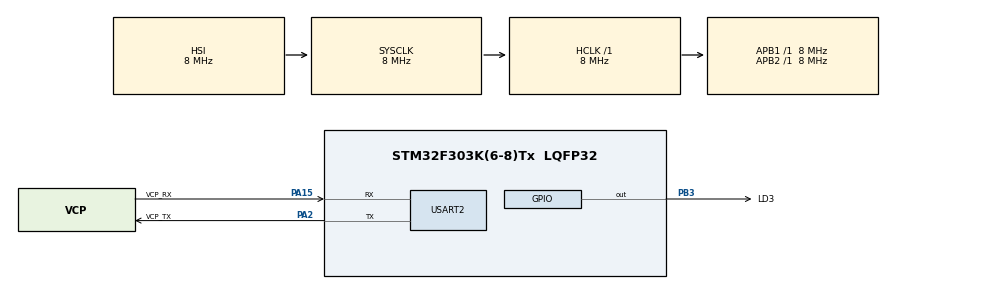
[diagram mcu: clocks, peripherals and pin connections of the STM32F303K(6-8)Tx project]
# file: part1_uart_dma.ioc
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Dma.Request0=USART2_RX
Dma.USART2_RX.0.Direction=DMA_PERIPH_TO_MEMORY
Dma.USART2_RX.0.Instance=DMA1_Channel6
Dma.USART2_RX.0.MemDataAlignment=DMA_MDATAALIGN_BYTE
Dma.USART2_RX.0.MemInc=DMA_MINC_ENABLE
Dma.USART2_RX.0.Mode=DMA_NORMAL
Dma.USART2_RX.0.PeriphDataAlignment=DMA_PDATAALIGN_BYTE
Dma.USART2_RX.0.PeriphInc=DMA_PINC_DISABLE
Dma.USART2_RX.0.Priority=DMA_PRIORITY_LOW
Mcu.Family=STM32F3
Mcu.Name=STM32F303K(6-8)Tx
Mcu.Package=LQFP32
NVIC.DMA1_Channel6_IRQn=true\:0\:0\:false\:false\:true\:false\:true\:true
NVIC.PriorityGroup=NVIC_PRIORITYGROUP_4
PA13.GPIO_Label=SWDIO
PA13.Mode=Serial_Wire
PA13.Signal=SYS_JTMS-SWDIO
PA14.GPIO_Label=SWCLK
PA14.Mode=Serial_Wire
PA14.Signal=SYS_JTCK-SWCLK
PA15.GPIO_Label=VCP_RX
PA15.Mode=Asynchronous
PA15.Signal=USART2_RX
PA2.GPIO_Label=VCP_TX
PA2.Mode=Asynchronous
PA2.Signal=USART2_TX
PB3.GPIO_Label=LD3
PB3.Signal=GPIO_Output
PF0\ /\ OSC_IN.GPIO_Label=MCO
PF0\ /\ OSC_IN.Mode=HSE-External-Clock-Source
PF0\ /\ OSC_IN.Signal=RCC_OSC_IN
ProjectManager.HeapSize=0x200
ProjectManager.StackSize=0x400
ProjectManager.TargetToolchain=STM32CubeIDE
RCC.AHBFreq_Value=8000000
RCC.APB1Freq_Value=8000000
RCC.APB2Freq_Value=8000000
RCC.CortexFreq_Value=8000000
RCC.HSE_VALUE=8000000
RCC.HSI_VALUE=8000000
RCC.SYSCLKFreq_VALUE=8000000
USART2.VirtualMode-Asynchronous=VM_ASYNC
board=NUCLEO-F303K8

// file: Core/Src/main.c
/* USER CODE BEGIN Header */
/**
  ******************************************************************************
  * @file           : main.c
  * @brief          : Main program body
  ******************************************************************************
  * @attention
  *
  * Copyright (c) 2024 STMicroelectronics.
  * All rights reserved.
  *
  * This software is licensed under terms that can be found in the LICENSE file
  * in the root directory of this software component.
  * If no LICENSE file comes with this software, it is provided AS-IS.
  *
  ******************************************************************************
  */
/* USER CODE END Header */
#include "main.h"

/* USER CODE BEGIN Includes */
#include <stdint.h>
#include <string.h>

/* USER CODE END Includes */

UART_HandleTypeDef huart2;
DMA_HandleTypeDef hdma_usart2_rx;

/* USER CODE BEGIN PV */

char uart_rx_char[2]; // Stores RX char and string terminator

/* USER CODE END PV */

void SystemClock_Config(void);
static void MX_GPIO_Init(void);
static void MX_DMA_Init(void);
static void MX_USART2_UART_Init(void);

int main(void)
{

  /* MCU Configuration--------------------------------------------------------*/

  /* Reset of all peripherals, Initializes the Flash interface and the Systick. */
  HAL_Init();

  /* Configure the system clock */
  SystemClock_Config();

  /* Initialize all configured peripherals */
  MX_GPIO_Init();
  MX_DMA_Init();
  MX_USART2_UART_Init();
  /* USER CODE BEGIN 2 */

  // Welcome Message
  char welcome_buf[] = "Write Anything on Serial Terminal\r\n";
  HAL_UART_Transmit(&huart2, (uint8_t *)welcome_buf, strlen(welcome_buf), 10);
  memset(welcome_buf, 0, sizeof(welcome_buf));

  // UART DMA RX Setup
  HAL_UART_Receive_DMA(&huart2, (uint8_t *)uart_rx_char, 1U);

  /* USER CODE END 2 */

  /* Infinite loop */
  while (1)
  {

    /* USER CODE BEGIN 3 */

    // Toggle LED to represent busy CPU
    HAL_GPIO_TogglePin(LD3_GPIO_Port, LD3_Pin);
    HAL_Delay(500);
  }
  /* USER CODE END 3 */
}

void SystemClock_Config(void)
{
  RCC_OscInitTypeDef RCC_OscInitStruct = {0};
  RCC_ClkInitTypeDef RCC_ClkInitStruct = {0};

  /** Initializes the RCC Oscillators according to the specified parameters
  * in the RCC_OscInitTypeDef structure.
  */
  RCC_OscInitStruct.OscillatorType = RCC_OSCILLATORTYPE_HSI;
  RCC_OscInitStruct.HSIState = RCC_HSI_ON;
  RCC_OscInitStruct.HSICalibrationValue = RCC_HSICALIBRATION_DEFAULT;
  RCC_OscInitStruct.PLL.PLLState = RCC_PLL_NONE;
  if (HAL_RCC_OscConfig(&RCC_OscInitStruct) != HAL_OK)
  {
    Error_Handler();
  }

  /** Initializes the CPU, AHB and APB buses clocks
  */
  RCC_ClkInitStruct.ClockType = RCC_CLOCKTYPE_HCLK|RCC_CLOCKTYPE_SYSCLK
                              |RCC_CLOCKTYPE_PCLK1|RCC_CLOCKTYPE_PCLK2;
  RCC_ClkInitStruct.SYSCLKSource = RCC_SYSCLKSOURCE_HSI;
  RCC_ClkInitStruct.AHBCLKDivider = RCC_SYSCLK_DIV1;
  RCC_ClkInitStruct.APB1CLKDivider = RCC_HCLK_DIV1;
  RCC_ClkInitStruct.APB2CLKDivider = RCC_HCLK_DIV1;

  if (HAL_RCC_ClockConfig(&RCC_ClkInitStruct, FLASH_LATENCY_0) != HAL_OK)
  {
    Error_Handler();
  }
}

static void MX_USART2_UART_Init(void)
{

  huart2.Instance = USART2;
  huart2.Init.BaudRate = 38400;
  huart2.Init.WordLength = UART_WORDLENGTH_8B;
  huart2.Init.StopBits = UART_STOPBITS_1;
  huart2.Init.Parity = UART_PARITY_NONE;
  huart2.Init.Mode = UART_MODE_TX_RX;
  huart2.Init.HwFlowCtl = UART_HWCONTROL_NONE;
  huart2.Init.OverSampling = UART_OVERSAMPLING_16;
  huart2.Init.OneBitSampling = UART_ONE_BIT_SAMPLE_DISABLE;
  huart2.AdvancedInit.AdvFeatureInit = UART_ADVFEATURE_NO_INIT;
  if (HAL_UART_Init(&huart2) != HAL_OK)
  {
    Error_Handler();
  }

}

static void MX_DMA_Init(void)
{

  /* DMA controller clock enable */
  __HAL_RCC_DMA1_CLK_ENABLE();

  /* DMA interrupt init */
  /* DMA1_Channel6_IRQn interrupt configuration */
  HAL_NVIC_SetPriority(DMA1_Channel6_IRQn, 0, 0);
  HAL_NVIC_EnableIRQ(DMA1_Channel6_IRQn);

}

static void MX_GPIO_Init(void)
{
  GPIO_InitTypeDef GPIO_InitStruct = {0};

  /* GPIO Ports Clock Enable */
  __HAL_RCC_GPIOF_CLK_ENABLE();
  __HAL_RCC_GPIOA_CLK_ENABLE();
  __HAL_RCC_GPIOB_CLK_ENABLE();

  /*Configure GPIO pin Output Level */
  HAL_GPIO_WritePin(LD3_GPIO_Port, LD3_Pin, GPIO_PIN_RESET);

  /*Configure GPIO pin : LD3_Pin */
  GPIO_InitStruct.Pin = LD3_Pin;
  GPIO_InitStruct.Mode = GPIO_MODE_OUTPUT_PP;
  GPIO_InitStruct.Pull = GPIO_NOPULL;
  GPIO_InitStruct.Speed = GPIO_SPEED_FREQ_LOW;
  HAL_GPIO_Init(LD3_GPIO_Port, &GPIO_InitStruct);

}

/* USER CODE BEGIN 4 */

void HAL_UART_RxCpltCallback(UART_HandleTypeDef *huart) {

  // Circular buffer and pointer logic goes here
  HAL_UART_Transmit(&huart2, (uint8_t *)uart_rx_char, 1U, 10); // Simulate writing character to buffer

  // Reactivate UART DMA RX
  HAL_UART_Receive_DMA(&huart2, (uint8_t *)uart_rx_char, 1U); // Receive single char
}

/* USER CODE END 4 */

void Error_Handler(void)
{
  __disable_irq();
  while (1)
  {
  }
}
